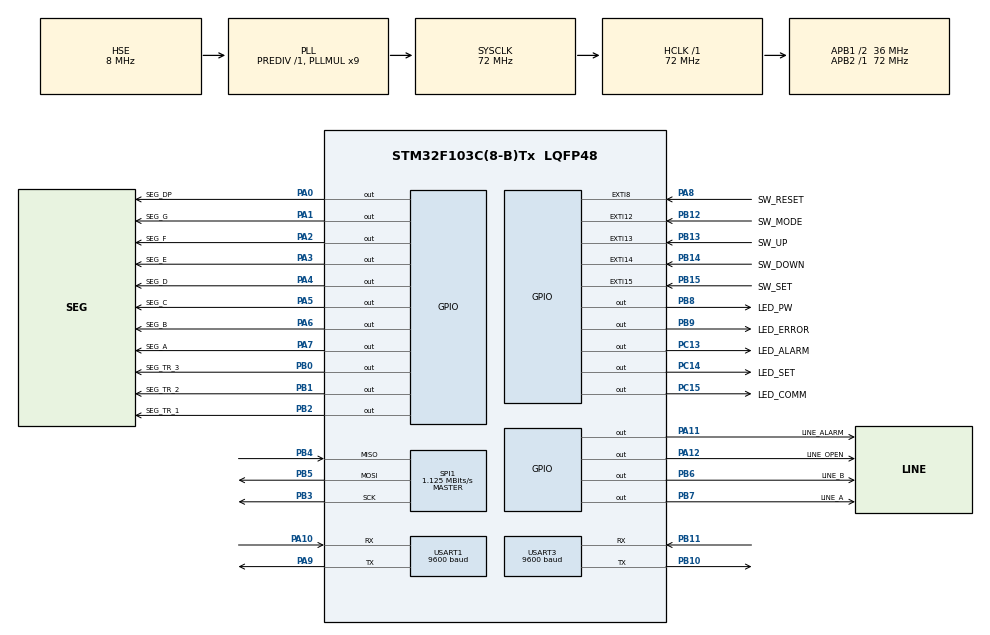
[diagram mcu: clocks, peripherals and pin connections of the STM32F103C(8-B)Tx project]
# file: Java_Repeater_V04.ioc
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Mcu.Family=STM32F1
Mcu.Name=STM32F103C(8-B)Tx
Mcu.Package=LQFP48
NVIC.EXTI15_10_IRQn=true\:0\:0\:false\:false\:true\:true\:true\:true
NVIC.EXTI9_5_IRQn=true\:0\:0\:false\:false\:true\:true\:true\:true
NVIC.PriorityGroup=NVIC_PRIORITYGROUP_4
NVIC.USART1_IRQn=true\:0\:0\:false\:true\:true\:1\:true\:true\:true
NVIC.USART3_IRQn=true\:0\:0\:false\:false\:true\:true\:true\:true
PA0-WKUP.GPIO_Label=SEG_DP
PA0-WKUP.Signal=GPIO_Output
PA1.GPIO_Label=SEG_G
PA1.Signal=GPIO_Output
PA10.Mode=Asynchronous
PA10.Signal=USART1_RX
PA11.GPIO_Label=LINE_ALARM
PA11.GPIO_ModeDefaultOutputPP=GPIO_MODE_OUTPUT_OD
PA11.GPIO_PuPd=GPIO_PULLUP
PA11.PinState=GPIO_PIN_SET
PA11.Signal=GPIO_Output
PA12.GPIO_Label=LINE_OPEN
PA12.GPIO_ModeDefaultOutputPP=GPIO_MODE_OUTPUT_OD
PA12.GPIO_PuPd=GPIO_PULLUP
PA12.PinState=GPIO_PIN_RESET
PA12.Signal=GPIO_Output
PA13.Mode=Serial_Wire
PA13.Signal=SYS_JTMS-SWDIO
PA14.Mode=Serial_Wire
PA14.Signal=SYS_JTCK-SWCLK
PA15.Signal=SPI1_NSS
PA2.GPIO_Label=SEG_F
PA2.Signal=GPIO_Output
PA3.GPIO_Label=SEG_E
PA3.Signal=GPIO_Output
PA4.GPIO_Label=SEG_D
PA4.Signal=GPIO_Output
PA5.GPIO_Label=SEG_C
PA5.Signal=GPIO_Output
PA6.GPIO_Label=SEG_B
PA6.Signal=GPIO_Output
PA7.GPIO_Label=SEG_A
PA7.Signal=GPIO_Output
PA8.GPIO_Label=SW_RESET
PA8.GPIO_ModeDefaultEXTI=GPIO_MODE_IT_RISING_FALLING
PA8.GPIO_PuPd=GPIO_PULLUP
PA8.Signal=GPXTI8
PA9.Mode=Asynchronous
PA9.Signal=USART1_TX
PB0.GPIO_Label=SEG_TR_3
PB0.Signal=GPIO_Output
PB1.GPIO_Label=SEG_TR_2
PB1.Signal=GPIO_Output
PB10.Mode=Asynchronous
PB10.Signal=USART3_TX
PB11.Mode=Asynchronous
PB11.Signal=USART3_RX
PB12.GPIO_Label=SW_MODE
PB12.GPIO_ModeDefaultEXTI=GPIO_MODE_IT_RISING_FALLING
PB12.GPIO_PuPd=GPIO_PULLUP
PB12.Signal=GPXTI12
PB13.GPIO_Label=SW_UP
PB13.GPIO_ModeDefaultEXTI=GPIO_MODE_IT_RISING_FALLING
PB13.GPIO_PuPd=GPIO_PULLUP
PB13.Signal=GPXTI13
PB14.GPIO_Label=SW_DOWN
PB14.GPIO_ModeDefaultEXTI=GPIO_MODE_IT_RISING_FALLING
PB14.GPIO_PuPd=GPIO_PULLUP
PB14.Signal=GPXTI14
PB15.GPIO_Label=SW_SET
PB15.GPIO_ModeDefaultEXTI=GPIO_MODE_IT_RISING_FALLING
PB15.GPIO_PuPd=GPIO_PULLUP
PB15.Signal=GPXTI15
PB2.GPIO_Label=SEG_TR_1
PB2.Signal=GPIO_Output
PB3.Mode=Full_Duplex_Master
PB3.Signal=SPI1_SCK
PB4.Mode=Full_Duplex_Master
PB4.Signal=SPI1_MISO
PB5.Mode=Full_Duplex_Master
PB5.Signal=SPI1_MOSI
PB6.GPIO_Label=LINE_B
PB6.GPIO_PuPd=GPIO_PULLDOWN
PB6.Signal=GPIO_Output
PB7.GPIO_Label=LINE_A
PB7.GPIO_PuPd=GPIO_PULLDOWN
PB7.Signal=GPIO_Output
PB8.GPIO_Label=LED_PW
PB8.GPIO_ModeDefaultOutputPP=GPIO_MODE_OUTPUT_OD
PB8.GPIO_PuPd=GPIO_PULLUP
PB8.Signal=GPIO_Output
PB9.GPIO_Label=LED_ERROR
PB9.GPIO_ModeDefaultOutputPP=GPIO_MODE_OUTPUT_OD
PB9.GPIO_PuPd=GPIO_PULLUP
PB9.Signal=GPIO_Output
PC13-TAMPER-RTC.GPIO_Label=LED_ALARM
PC13-TAMPER-RTC.GPIO_ModeDefaultOutputPP=GPIO_MODE_OUTPUT_OD
PC13-TAMPER-RTC.GPIO_PuPd=GPIO_PULLUP
PC13-TAMPER-RTC.PinState=GPIO_PIN_RESET
PC13-TAMPER-RTC.Signal=GPIO_Output
PC14-OSC32_IN.GPIO_Label=LED_SET
PC14-OSC32_IN.GPIO_ModeDefaultOutputPP=GPIO_MODE_OUTPUT_OD
PC14-OSC32_IN.GPIO_PuPd=GPIO_PULLUP
PC14-OSC32_IN.Signal=GPIO_Output
PC15-OSC32_OUT.GPIO_Label=LED_COMM
PC15-OSC32_OUT.GPIO_ModeDefaultOutputPP=GPIO_MODE_OUTPUT_OD
PC15-OSC32_OUT.GPIO_PuPd=GPIO_PULLUP
PC15-OSC32_OUT.Signal=GPIO_Output
PD0-OSC_IN.Mode=HSE-External-Oscillator
PD0-OSC_IN.Signal=RCC_OSC_IN
PD1-OSC_OUT.Mode=HSE-External-Oscillator
PD1-OSC_OUT.Signal=RCC_OSC_OUT
ProjectManager.HeapSize=0x200
ProjectManager.StackSize=0x400
ProjectManager.TargetToolchain=CMake
RCC.AHBFreq_Value=72000000
RCC.APB1CLKDivider=RCC_HCLK_DIV2
RCC.APB1Freq_Value=36000000
RCC.APB1TimFreq_Value=72000000
RCC.APB2Freq_Value=72000000
RCC.APB2TimFreq_Value=72000000
RCC.HCLKFreq_Value=72000000
RCC.PLLMUL=RCC_PLL_MUL9
RCC.PLLSourceVirtual=RCC_PLLSOURCE_HSE
RCC.SYSCLKFreq_VALUE=72000000
RCC.SYSCLKSource=RCC_SYSCLKSOURCE_PLLCLK
RCC.USBFreq_Value=72000000
SPI1.BaudRatePrescaler=SPI_BAUDRATEPRESCALER_64
SPI1.CRCCalculation=SPI_CRCCALCULATION_ENABLE
SPI1.CalculateBaudRate=1.125 MBits/s
SPI1.Direction=SPI_DIRECTION_2LINES
SPI1.Mode=SPI_MODE_MASTER
SPI1.VirtualType=VM_MASTER
USART1.BaudRate=9600
USART1.VirtualMode=VM_ASYNC
USART3.BaudRate=9600
USART3.VirtualMode=VM_ASYNC
VP_CRC_VS_CRC.Mode=CRC_Activate
board=custom

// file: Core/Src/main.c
/* USER CODE BEGIN Header */
/**
  ******************************************************************************
  * @file           : main.c
  * @brief          : Main program body
  ******************************************************************************
  * @attention
  *
  * Copyright (c) 2025 STMicroelectronics.
  * All rights reserved.
  *
  * This software is licensed under terms that can be found in the LICENSE file
  * in the root directory of this software component.
  * If no LICENSE file comes with this software, it is provided AS-IS.
  *
  ******************************************************************************
  */
/* USER CODE END Header */
#include "main.h"

/* USER CODE BEGIN Includes */
#include "App/Global.h"
#include "App/app_core.h"
/* USER CODE END Includes */

CRC_HandleTypeDef hcrc;

SPI_HandleTypeDef hspi1;

UART_HandleTypeDef huart1;
UART_HandleTypeDef huart3;

void SystemClock_Config(void);
static void MX_GPIO_Init(void);
static void MX_SPI1_Init(void);
static void MX_USART1_UART_Init(void);
static void MX_USART3_UART_Init(void);
static void MX_CRC_Init(void);
static void MX_NVIC_Init(void);

int main(void)
{

  /* MCU Configuration--------------------------------------------------------*/

  /* Reset of all peripherals, Initializes the Flash interface and the Systick. */
  HAL_Init();

  /* Configure the system clock */
  SystemClock_Config();

  /* Initialize all configured peripherals */
  MX_GPIO_Init();
  MX_SPI1_Init();
  MX_USART1_UART_Init();
  MX_USART3_UART_Init();
  MX_CRC_Init();

  /* Initialize interrupts */
  MX_NVIC_Init();

  /* Infinite loop */
  while (1)
  {

    /* USER CODE BEGIN 3 */
	  AppCore();

  }
  /* USER CODE END 3 */
}

void SystemClock_Config(void)
{
  RCC_OscInitTypeDef RCC_OscInitStruct = {0};
  RCC_ClkInitTypeDef RCC_ClkInitStruct = {0};

  /** Initializes the RCC Oscillators according to the specified parameters
  * in the RCC_OscInitTypeDef structure.
  */
  RCC_OscInitStruct.OscillatorType = RCC_OSCILLATORTYPE_HSE;
  RCC_OscInitStruct.HSEState = RCC_HSE_ON;
  RCC_OscInitStruct.HSEPredivValue = RCC_HSE_PREDIV_DIV1;
  RCC_OscInitStruct.HSIState = RCC_HSI_ON;
  RCC_OscInitStruct.PLL.PLLState = RCC_PLL_ON;
  RCC_OscInitStruct.PLL.PLLSource = RCC_PLLSOURCE_HSE;
  RCC_OscInitStruct.PLL.PLLMUL = RCC_PLL_MUL9;
  if (HAL_RCC_OscConfig(&RCC_OscInitStruct) != HAL_OK)
  {
    Error_Handler();
  }

  /** Initializes the CPU, AHB and APB buses clocks
  */
  RCC_ClkInitStruct.ClockType = RCC_CLOCKTYPE_HCLK|RCC_CLOCKTYPE_SYSCLK
                              |RCC_CLOCKTYPE_PCLK1|RCC_CLOCKTYPE_PCLK2;
  RCC_ClkInitStruct.SYSCLKSource = RCC_SYSCLKSOURCE_PLLCLK;
  RCC_ClkInitStruct.AHBCLKDivider = RCC_SYSCLK_DIV1;
  RCC_ClkInitStruct.APB1CLKDivider = RCC_HCLK_DIV2;
  RCC_ClkInitStruct.APB2CLKDivider = RCC_HCLK_DIV1;

  if (HAL_RCC_ClockConfig(&RCC_ClkInitStruct, FLASH_LATENCY_2) != HAL_OK)
  {
    Error_Handler();
  }
}

/**
  * @brief NVIC Configuration.
  * @retval None
  */
static void MX_NVIC_Init(void)
{
  /* USART1_IRQn interrupt configuration */
  HAL_NVIC_SetPriority(USART1_IRQn, 0, 0);
  HAL_NVIC_EnableIRQ(USART1_IRQn);
}

static void MX_CRC_Init(void)
{

  hcrc.Instance = CRC;
  if (HAL_CRC_Init(&hcrc) != HAL_OK)
  {
    Error_Handler();
  }

}

static void MX_SPI1_Init(void)
{

  /* SPI1 parameter configuration*/
  hspi1.Instance = SPI1;
  hspi1.Init.Mode = SPI_MODE_MASTER;
  hspi1.Init.Direction = SPI_DIRECTION_2LINES;
  hspi1.Init.DataSize = SPI_DATASIZE_8BIT;
  hspi1.Init.CLKPolarity = SPI_POLARITY_LOW;
  hspi1.Init.CLKPhase = SPI_PHASE_1EDGE;
  hspi1.Init.NSS = SPI_NSS_SOFT;
  hspi1.Init.BaudRatePrescaler = SPI_BAUDRATEPRESCALER_64;
  hspi1.Init.FirstBit = SPI_FIRSTBIT_MSB;
  hspi1.Init.TIMode = SPI_TIMODE_DISABLE;
  hspi1.Init.CRCCalculation = SPI_CRCCALCULATION_ENABLE;
  hspi1.Init.CRCPolynomial = 10;
  if (HAL_SPI_Init(&hspi1) != HAL_OK)
  {
    Error_Handler();
  }

}

static void MX_USART1_UART_Init(void)
{

  huart1.Instance = USART1;
  huart1.Init.BaudRate = 9600;
  huart1.Init.WordLength = UART_WORDLENGTH_8B;
  huart1.Init.StopBits = UART_STOPBITS_1;
  huart1.Init.Parity = UART_PARITY_NONE;
  huart1.Init.Mode = UART_MODE_TX_RX;
  huart1.Init.HwFlowCtl = UART_HWCONTROL_NONE;
  huart1.Init.OverSampling = UART_OVERSAMPLING_16;
  if (HAL_UART_Init(&huart1) != HAL_OK)
  {
    Error_Handler();
  }

}

static void MX_USART3_UART_Init(void)
{

  huart3.Instance = USART3;
  huart3.Init.BaudRate = 9600;
  huart3.Init.WordLength = UART_WORDLENGTH_8B;
  huart3.Init.StopBits = UART_STOPBITS_1;
  huart3.Init.Parity = UART_PARITY_NONE;
  huart3.Init.Mode = UART_MODE_TX_RX;
  huart3.Init.HwFlowCtl = UART_HWCONTROL_NONE;
  huart3.Init.OverSampling = UART_OVERSAMPLING_16;
  if (HAL_UART_Init(&huart3) != HAL_OK)
  {
    Error_Handler();
  }

}

static void MX_GPIO_Init(void)
{
  GPIO_InitTypeDef GPIO_InitStruct = {0};

  /* GPIO Ports Clock Enable */
  __HAL_RCC_GPIOC_CLK_ENABLE();
  __HAL_RCC_GPIOD_CLK_ENABLE();
  __HAL_RCC_GPIOA_CLK_ENABLE();
  __HAL_RCC_GPIOB_CLK_ENABLE();

  /*Configure GPIO pin Output Level */
  HAL_GPIO_WritePin(GPIOC, LED_ALARM_Pin|LED_SET_Pin|LED_COMM_Pin, GPIO_PIN_RESET);

  /*Configure GPIO pin Output Level */
  HAL_GPIO_WritePin(GPIOA, SEG_DP_Pin|SEG_G_Pin|SEG_F_Pin|SEG_E_Pin
                          |SEG_D_Pin|SEG_C_Pin|SEG_B_Pin|SEG_A_Pin
                          |LINE_OPEN_Pin, GPIO_PIN_RESET);

  /*Configure GPIO pin Output Level */
  HAL_GPIO_WritePin(GPIOB, SEG_TR_3_Pin|SEG_TR_2_Pin|SEG_TR_1_Pin|LINE_B_Pin
                          |LINE_A_Pin|LED_PW_Pin|LED_ERROR_Pin, GPIO_PIN_RESET);

  /*Configure GPIO pin Output Level */
  HAL_GPIO_WritePin(LINE_ALARM_GPIO_Port, LINE_ALARM_Pin, GPIO_PIN_SET);

  /*Configure GPIO pins : LED_ALARM_Pin LED_SET_Pin LED_COMM_Pin */
  GPIO_InitStruct.Pin = LED_ALARM_Pin|LED_SET_Pin|LED_COMM_Pin;
  GPIO_InitStruct.Mode = GPIO_MODE_OUTPUT_OD;
  GPIO_InitStruct.Pull = GPIO_PULLUP;
  GPIO_InitStruct.Speed = GPIO_SPEED_FREQ_LOW;
  HAL_GPIO_Init(GPIOC, &GPIO_InitStruct);

  /*Configure GPIO pins : SEG_DP_Pin SEG_G_Pin SEG_F_Pin SEG_E_Pin
                           SEG_D_Pin SEG_C_Pin SEG_B_Pin SEG_A_Pin */
  GPIO_InitStruct.Pin = SEG_DP_Pin|SEG_G_Pin|SEG_F_Pin|SEG_E_Pin
                          |SEG_D_Pin|SEG_C_Pin|SEG_B_Pin|SEG_A_Pin;
  GPIO_InitStruct.Mode = GPIO_MODE_OUTPUT_PP;
  GPIO_InitStruct.Pull = GPIO_NOPULL;
  GPIO_InitStruct.Speed = GPIO_SPEED_FREQ_LOW;
  HAL_GPIO_Init(GPIOA, &GPIO_InitStruct);

  /*Configure GPIO pins : SEG_TR_3_Pin SEG_TR_2_Pin SEG_TR_1_Pin */
  GPIO_InitStruct.Pin = SEG_TR_3_Pin|SEG_TR_2_Pin|SEG_TR_1_Pin;
  GPIO_InitStruct.Mode = GPIO_MODE_OUTPUT_PP;
  GPIO_InitStruct.Pull = GPIO_NOPULL;
  GPIO_InitStruct.Speed = GPIO_SPEED_FREQ_LOW;
  HAL_GPIO_Init(GPIOB, &GPIO_InitStruct);

  /*Configure GPIO pins : SW_MODE_Pin SW_UP_Pin SW_DOWN_Pin SW_SET_Pin */
  GPIO_InitStruct.Pin = SW_MODE_Pin|SW_UP_Pin|SW_DOWN_Pin|SW_SET_Pin;
  GPIO_InitStruct.Mode = GPIO_MODE_IT_RISING_FALLING;
  GPIO_InitStruct.Pull = GPIO_PULLUP;
  HAL_GPIO_Init(GPIOB, &GPIO_InitStruct);

  /*Configure GPIO pin : SW_RESET_Pin */
  GPIO_InitStruct.Pin = SW_RESET_Pin;
  GPIO_InitStruct.Mode = GPIO_MODE_IT_RISING_FALLING;
  GPIO_InitStruct.Pull = GPIO_PULLUP;
  HAL_GPIO_Init(SW_RESET_GPIO_Port, &GPIO_InitStruct);

  /*Configure GPIO pins : LINE_ALARM_Pin LINE_OPEN_Pin */
  GPIO_InitStruct.Pin = LINE_ALARM_Pin|LINE_OPEN_Pin;
  GPIO_InitStruct.Mode = GPIO_MODE_OUTPUT_OD;
  GPIO_InitStruct.Pull = GPIO_PULLUP;
  GPIO_InitStruct.Speed = GPIO_SPEED_FREQ_LOW;
  HAL_GPIO_Init(GPIOA, &GPIO_InitStruct);

  /*Configure GPIO pins : LINE_B_Pin LINE_A_Pin */
  GPIO_InitStruct.Pin = LINE_B_Pin|LINE_A_Pin;
  GPIO_InitStruct.Mode = GPIO_MODE_OUTPUT_PP;
  GPIO_InitStruct.Pull = GPIO_PULLDOWN;
  GPIO_InitStruct.Speed = GPIO_SPEED_FREQ_LOW;
  HAL_GPIO_Init(GPIOB, &GPIO_InitStruct);

  /*Configure GPIO pins : LED_PW_Pin LED_ERROR_Pin */
  GPIO_InitStruct.Pin = LED_PW_Pin|LED_ERROR_Pin;
  GPIO_InitStruct.Mode = GPIO_MODE_OUTPUT_OD;
  GPIO_InitStruct.Pull = GPIO_PULLUP;
  GPIO_InitStruct.Speed = GPIO_SPEED_FREQ_LOW;
  HAL_GPIO_Init(GPIOB, &GPIO_InitStruct);

  /* EXTI interrupt init*/
  HAL_NVIC_SetPriority(EXTI9_5_IRQn, 0, 0);
  HAL_NVIC_EnableIRQ(EXTI9_5_IRQn);

  HAL_NVIC_SetPriority(EXTI15_10_IRQn, 0, 0);
  HAL_NVIC_EnableIRQ(EXTI15_10_IRQn);

}

void Error_Handler(void)
{
  __disable_irq();
  while (1)
  {
  }
}
